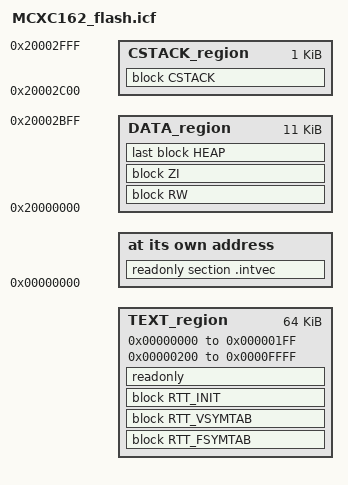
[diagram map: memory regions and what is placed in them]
/*
** ###################################################################
**     Processors:          MCXC162VFG
**                          MCXC162VFK
**                          MCXC162VFM
**                          MCXC162VFT
**                          MCXC162VLF
**
**     Compiler:            IAR ANSI C/C++ Compiler for ARM
**     Reference manual:    MCXAP144M180FS6_RM_Rev.1
**     Version:             rev. 1.0, 2024-03-26
**     Build:               b260326
**
**     Abstract:
**         Linker file for the IAR ANSI C/C++ Compiler for ARM
**
**     Copyright 2016 Freescale Semiconductor, Inc.
**     Copyright 2016-2026 NXP
**     SPDX-License-Identifier: BSD-3-Clause
**
**     http:                 www.nxp.com
**     mail:                 support@nxp.com
**
** ###################################################################
*/


/* Stack and Heap Sizes */
if (isdefinedsymbol(__stack_size__)) {
  define symbol __size_cstack__        = __stack_size__;
} else {
  define symbol __size_cstack__        = 0x0400;
}

if (isdefinedsymbol(__heap_size__)) {
  define symbol __size_heap__          = __heap_size__;
} else {
  define symbol __size_heap__          = 0;
}

define symbol m_interrupts_start               = 0x00000000;
define symbol m_interrupts_end                 = 0x000001FF;

define symbol m_text_start                     = 0x00000200;
define symbol m_text_end                       = 0x0000FFFF;

define symbol m_data_start                     = 0x20000000;
define symbol m_data_end                       = 0x20002FFF;
define exported symbol __RTT_HEAP_END           = m_data_end-__size_cstack__+1;

define memory mem with size = 4G;

define region TEXT_region             = mem:[from m_interrupts_start to m_interrupts_end]
                                      | mem:[from m_text_start to m_text_end];
define region DATA_region = mem:[from m_data_start to m_data_end-__size_cstack__];

define region CSTACK_region = mem:[from m_data_end-__size_cstack__+1 to m_data_end];
if (isdefinedsymbol(__use_shmem__)) {
  define region rpmsg_sh_mem_region     = mem:[from rpmsg_sh_mem_start to rpmsg_sh_mem_end];
}

define block CSTACK    with alignment = 8, size = __size_cstack__   { };
define block HEAP      with alignment = 8, size = __size_heap__     { };
define block RW        { readwrite };
define block ZI        { zi };
define root section RTT_FSYMTAB_START { public_notype __fsymtab_start: };
define root section RTT_FSYMTAB_END { public_notype __fsymtab_end: };
define root section RTT_VSYMTAB_START { public_notype __vsymtab_start: };
define root section RTT_VSYMTAB_END { public_notype __vsymtab_end: };
define root section RTT_INIT_START { public_notype __rt_init_start: };
define root section RTT_INIT_END { public_notype __rt_init_end: };

define block RTT_FSYMTAB with fixed order { section RTT_FSYMTAB_START,
                                            readonly section FSymTab,
                                            section RTT_FSYMTAB_END };
define block RTT_VSYMTAB with fixed order { section RTT_VSYMTAB_START,
                                            readonly section VSymTab,
                                            section RTT_VSYMTAB_END };
define block RTT_INIT_CONTENT with alphabetical order { readonly section .rti_fn* };
define block RTT_INIT with fixed order { section RTT_INIT_START,
                                         block RTT_INIT_CONTENT,
                                         section RTT_INIT_END };

initialize by copy { readwrite, section .textrw };

if (isdefinedsymbol(__USE_DLIB_PERTHREAD))
{
  /* Required in a multi-threaded application */
  initialize by copy with packing = none { section __DLIB_PERTHREAD };
}


place at address mem: m_interrupts_start    { readonly section .intvec };
place in TEXT_region                        { block RTT_FSYMTAB };
place in TEXT_region                        { block RTT_VSYMTAB };
place in TEXT_region                        { block RTT_INIT };
place in TEXT_region                        { readonly };
place in DATA_region                        { block RW };
place in DATA_region                        { block ZI };
place in DATA_region                        { last block HEAP };
place in CSTACK_region                      { block CSTACK };

keep { section FSymTab, section VSymTab, section .rti_fn* };


